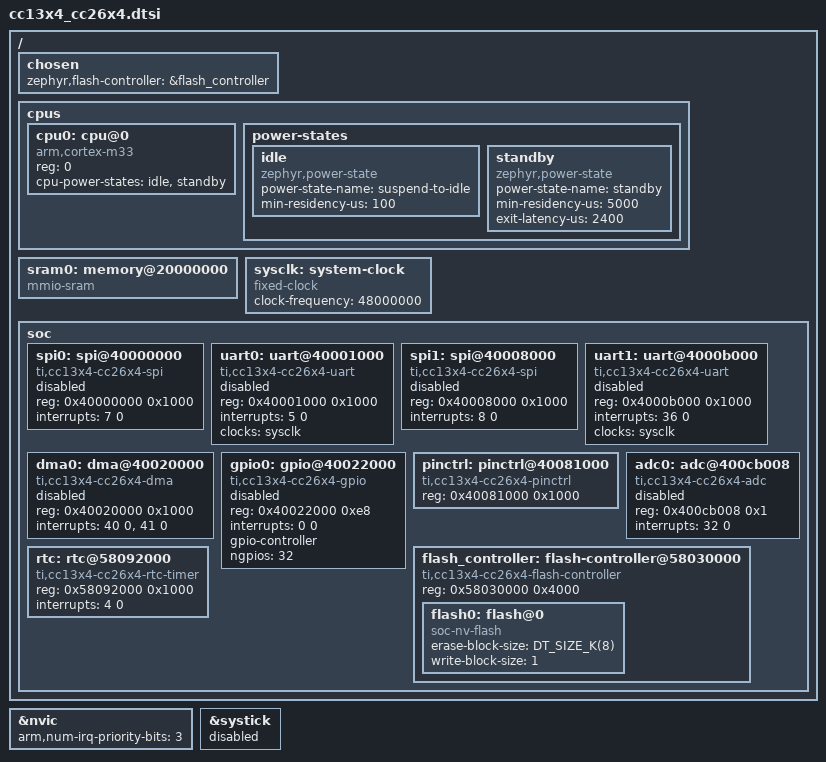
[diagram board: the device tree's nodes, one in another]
/*
 * Copyright (c) 2026 Texas Instruments Incorporated
 *
 * SPDX-License-Identifier: Apache-2.0
 */

#include <arm/armv8-m.dtsi>
#include <zephyr/dt-bindings/gpio/gpio.h>

/ {
	chosen {
		zephyr,flash-controller = &flash_controller;
	};

	cpus {
		#address-cells = <1>;
		#size-cells = <0>;

		cpu0: cpu@0 {
			device_type = "cpu";
			compatible = "arm,cortex-m33";
			reg = <0>;
			cpu-power-states = <&idle &standby>;
		};

		power-states {
			idle: idle {
				compatible = "zephyr,power-state";
				power-state-name = "suspend-to-idle";
				min-residency-us = <100>;
			};

			standby: standby {
				compatible = "zephyr,power-state";
				power-state-name = "standby";
				min-residency-us = <5000>;
				exit-latency-us = <2400>;
			};
		};
	};

	sram0: memory@20000000 {
		compatible = "mmio-sram";
	};

	sysclk: system-clock {
		compatible = "fixed-clock";
		clock-frequency = <48000000>;
		#clock-cells = <0>;
	};

	soc {
		spi0: spi@40000000 {
			compatible = "ti,cc13x4-cc26x4-spi";
			reg = <0x40000000 0x1000>;
			interrupts = <7 0>;
			#address-cells = <1>;
			#size-cells = <0>;
			status = "disabled";
		};

		uart0: uart@40001000 {
			compatible = "ti,cc13x4-cc26x4-uart";
			reg = <0x40001000 0x1000>;
			interrupts = <5 0>;
			clocks = <&sysclk>;
			status = "disabled";
		};

		spi1: spi@40008000 {
			compatible = "ti,cc13x4-cc26x4-spi";
			reg = <0x40008000 0x1000>;
			interrupts = <8 0>;
			#address-cells = <1>;
			#size-cells = <0>;
			status = "disabled";
		};

		uart1: uart@4000b000 {
			compatible = "ti,cc13x4-cc26x4-uart";
			reg = <0x4000b000 0x1000>;
			interrupts = <36 0>;
			clocks = <&sysclk>;
			status = "disabled";
		};

		dma0: dma@40020000 {
			compatible = "ti,cc13x4-cc26x4-dma";
			reg = <0x40020000 0x1000>;
			interrupts = <40 0>, <41 0>;
			#dma-cells = <2>;
			status = "disabled";
		};

		gpio0: gpio@40022000 {
			compatible = "ti,cc13x4-cc26x4-gpio";
			reg = <0x40022000 0xe8>;
			interrupts = <0 0>;
			status = "disabled";
			gpio-controller;
			#gpio-cells = <2>;
			ngpios = <32>; /* Only [DIO0, DIO31] are supported */
		};

		pinctrl: pinctrl@40081000 {
			compatible = "ti,cc13x4-cc26x4-pinctrl";
			reg = <0x40081000 0x1000>;
		};

		adc0: adc@400cb008 {
			compatible = "ti,cc13x4-cc26x4-adc";
			reg = <0x400cb008 0x1>; /* not used by the driver */
			interrupts = <32 0>;
			status = "disabled";
			#io-channel-cells = <1>;
		};

		flash_controller: flash-controller@58030000 {
			compatible = "ti,cc13x4-cc26x4-flash-controller";
			reg = <0x58030000 0x4000>;
			#address-cells = <1>;
			#size-cells = <1>;

			flash0: flash@0 {
				compatible = "soc-nv-flash";
				erase-block-size = <DT_SIZE_K(8)>;
				write-block-size = <1>;
			};
		};

		rtc: rtc@58092000 {
			compatible = "ti,cc13x4-cc26x4-rtc-timer";
			reg = <0x58092000 0x1000>;
			interrupts = <4 0>;
			status = "okay";
		};
	};
};

&nvic {
	arm,num-irq-priority-bits = <3>;
};

&systick {
	status = "disabled";
};
